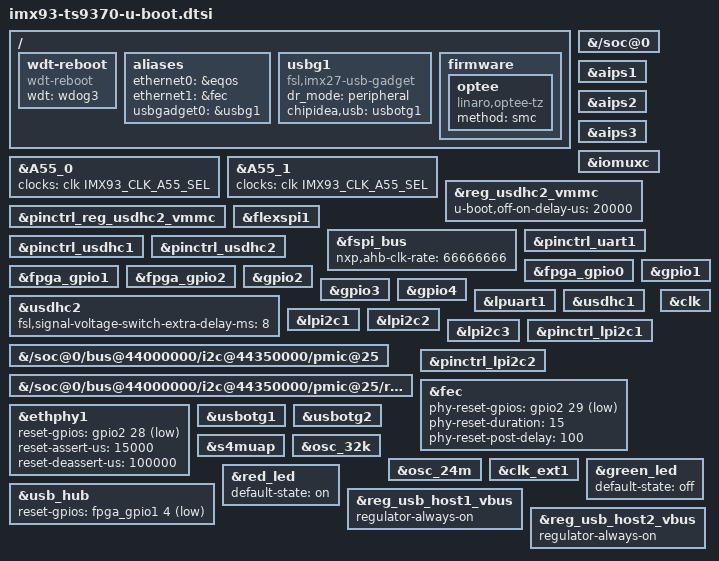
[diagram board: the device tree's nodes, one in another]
// SPDX-License-Identifier: GPL-2.0+
/*
 * Copyright 2022 NXP
 */

#include "imx93-u-boot.dtsi"

/ {
	wdt-reboot {
		compatible = "wdt-reboot";
		wdt = <&wdog3>;
		bootph-pre-ram;
		bootph-some-ram;
	};

	aliases {
		ethernet0 = &eqos;
		ethernet1 = &fec;
		usbgadget0 = &usbg1;
	};

	usbg1: usbg1 {
		compatible = "fsl,imx27-usb-gadget";
		dr_mode = "peripheral";
		chipidea,usb = <&usbotg1>;
		status = "okay";
	};

	firmware {
		optee {
			compatible = "linaro,optee-tz";
			method = "smc";
		};
	};
};

&A55_0 {
	clocks = <&clk IMX93_CLK_A55_SEL>;
};

&A55_1 {
	clocks = <&clk IMX93_CLK_A55_SEL>;
};

&{/soc@0} {
	bootph-all;
	bootph-pre-ram;
};

&aips1 {
	bootph-pre-ram;
	bootph-all;
};

&aips2 {
	bootph-pre-ram;
	bootph-some-ram;
};

&aips3 {
	bootph-pre-ram;
	bootph-some-ram;
};

&iomuxc {
	bootph-pre-ram;
	bootph-some-ram;
};

&reg_usdhc2_vmmc {
	u-boot,off-on-delay-us = <20000>;
	bootph-pre-ram;
};

&pinctrl_reg_usdhc2_vmmc {
	bootph-pre-ram;
};

&flexspi1 {
	bootph-pre-ram;
};

&fspi_bus {
	bootph-pre-ram;
	bootph-some-ram;
	nxp,ahb-clk-rate = <66666666>;
};

&pinctrl_uart1 {
	bootph-pre-ram;
	bootph-some-ram;
};

&pinctrl_usdhc1 {
	bootph-pre-ram;
};

&pinctrl_usdhc2 {
	bootph-pre-ram;
};

&fpga_gpio0 {
	bootph-some-ram;
};

&fpga_gpio1 {
	bootph-some-ram;
};

&fpga_gpio2 {
	bootph-some-ram;
};

&gpio1 {
	bootph-pre-ram;
	bootph-some-ram;
};

&gpio2 {
	bootph-pre-ram;
	bootph-some-ram;
};

&gpio3 {
	bootph-pre-ram;
	bootph-some-ram;
};

&gpio4 {
	bootph-pre-ram;
	bootph-some-ram;
};

&lpuart1 {
	bootph-pre-ram;
	bootph-some-ram;
};

&usdhc1 {
	bootph-pre-ram;
};

&usdhc2 {
	bootph-pre-ram;
	fsl,signal-voltage-switch-extra-delay-ms = <8>;
};

&lpi2c1 {
	bootph-pre-ram;
};

&lpi2c2 {
	bootph-pre-ram;
};

&lpi2c3 {
	bootph-pre-ram;
};

&{/soc@0/bus@44000000/i2c@44350000/pmic@25} {
	bootph-pre-ram;
};

&{/soc@0/bus@44000000/i2c@44350000/pmic@25/regulators} {
	bootph-pre-ram;
};

&pinctrl_lpi2c1 {
	bootph-pre-ram;
};

&pinctrl_lpi2c2 {
	bootph-pre-ram;
};

/* ETH2_RESET# is passed through the FPGA to GPIO_19 */
&fec {
	phy-reset-gpios = <&gpio2 29 GPIO_ACTIVE_LOW>;
	phy-reset-duration = <15>;
	phy-reset-post-delay = <100>;
};

/* ETH1_RESET# is passed through the FPGA to GPIO_20 */
&ethphy1 {
	reset-gpios = <&gpio2 28 GPIO_ACTIVE_LOW>;
	reset-assert-us = <15000>;
	reset-deassert-us = <100000>;
};

&usbotg1 {
	status = "okay";
};

&usbotg2 {
	status = "okay";
};

&s4muap {
	bootph-pre-ram;
	bootph-some-ram;
	status = "okay";
};

&clk {
	bootph-all;
	bootph-pre-ram;
	/delete-property/ assigned-clocks;
	/delete-property/ assigned-clock-rates;
	/delete-property/ assigned-clock-parents;
};

&osc_32k {
	bootph-all;
	bootph-pre-ram;
};

&osc_24m {
	bootph-all;
	bootph-pre-ram;
};

&clk_ext1 {
	bootph-all;
	bootph-pre-ram;
};

&usb_hub {
	reset-gpios = <&fpga_gpio1 4 GPIO_ACTIVE_LOW>;
	bootph-some-ram;
};

&green_led {
	default-state = "off";
};

&red_led {
	default-state = "on";
};

/* Setting these USB regulators to 'always-on' until u-boot adds support for 
 * usb vbus ports */
&reg_usb_host1_vbus {
	regulator-always-on;
};

&reg_usb_host2_vbus {
	regulator-always-on;
};
